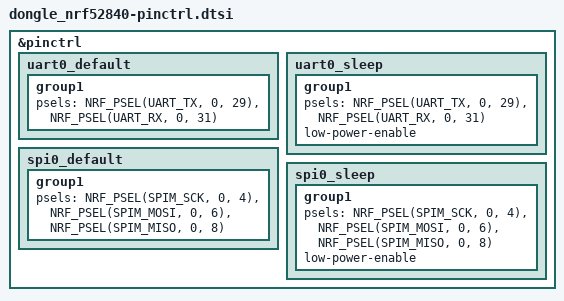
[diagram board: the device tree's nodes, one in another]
/*
 * SPDX-FileCopyrightText: Copyright (c) 2023 GARDENA GmbH
 * SPDX-License-Identifier: GPL-3.0-or-later
 */

&pinctrl {
	uart0_default: uart0_default {
		group1 {
			psels = <NRF_PSEL(UART_TX, 0, 29)>,
				<NRF_PSEL(UART_RX, 0, 31)>;
		};
	};

	uart0_sleep: uart0_sleep {
		group1 {
			psels = <NRF_PSEL(UART_TX, 0, 29)>,
				<NRF_PSEL(UART_RX, 0, 31)>;
			low-power-enable;
		};
	};

	spi0_default: spi0_default {
		group1 {
			psels = <NRF_PSEL(SPIM_SCK, 0, 4)>,
				<NRF_PSEL(SPIM_MOSI, 0, 6)>,
				<NRF_PSEL(SPIM_MISO, 0, 8)>;
		};
	};

	spi0_sleep: spi0_sleep {
		group1 {
			psels = <NRF_PSEL(SPIM_SCK, 0, 4)>,
				<NRF_PSEL(SPIM_MOSI, 0, 6)>,
				<NRF_PSEL(SPIM_MISO, 0, 8)>;
			low-power-enable;
		};
	};

};
